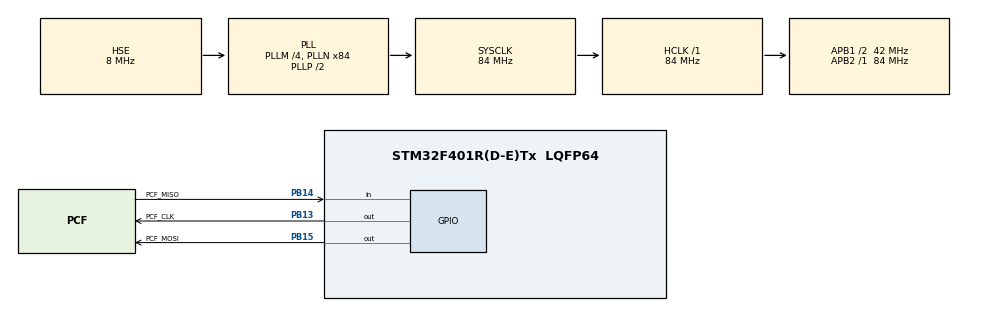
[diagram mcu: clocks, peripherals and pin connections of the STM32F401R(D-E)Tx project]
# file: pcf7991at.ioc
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Mcu.Family=STM32F4
Mcu.Name=STM32F401R(D-E)Tx
Mcu.Package=LQFP64
NVIC.PriorityGroup=NVIC_PRIORITYGROUP_4
PB13.GPIO_Label=PCF_CLK
PB13.GPIO_ModeDefaultOutputPP=GPIO_MODE_OUTPUT_OD
PB13.GPIO_PuPd=GPIO_NOPULL
PB13.GPIO_Speed=GPIO_SPEED_FREQ_HIGH
PB13.Signal=GPIO_Output
PB14.GPIO_Label=PCF_MISO
PB14.Signal=GPIO_Input
PB15.GPIO_Label=PCF_MOSI
PB15.GPIO_ModeDefaultOutputPP=GPIO_MODE_OUTPUT_OD
PB15.GPIO_PuPd=GPIO_NOPULL
PB15.GPIO_Speed=GPIO_SPEED_FREQ_HIGH
PB15.Signal=GPIO_Output
PH0\ -\ OSC_IN.Mode=HSE-External-Oscillator
PH0\ -\ OSC_IN.Signal=RCC_OSC_IN
PH1\ -\ OSC_OUT.Mode=HSE-External-Oscillator
PH1\ -\ OSC_OUT.Signal=RCC_OSC_OUT
ProjectManager.HeapSize=0x200
ProjectManager.StackSize=0x400
ProjectManager.TargetToolchain=STM32CubeIDE
RCC.48MHZClocksFreq_Value=42000000
RCC.AHBFreq_Value=84000000
RCC.APB1CLKDivider=RCC_HCLK_DIV2
RCC.APB1Freq_Value=42000000
RCC.APB1TimFreq_Value=84000000
RCC.APB2Freq_Value=84000000
RCC.APB2TimFreq_Value=84000000
RCC.CortexFreq_Value=84000000
RCC.HCLKFreq_Value=84000000
RCC.HSE_VALUE=8000000
RCC.HSI_VALUE=16000000
RCC.LSE_VALUE=32768
RCC.PLLM=4
RCC.PLLN=84
RCC.PLLSourceVirtual=RCC_PLLSOURCE_HSE
RCC.SYSCLKFreq_VALUE=84000000
RCC.SYSCLKSource=RCC_SYSCLKSOURCE_PLLCLK
RCC.VCOOutputFreq_Value=168000000
board=custom

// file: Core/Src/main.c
/* USER CODE BEGIN Header */
/**
  ******************************************************************************
  * @file           : main.c
  * @brief          : Main program body
  ******************************************************************************
  */
/* USER CODE END Header */
#include "main.h"

void SystemClock_Config(void);
static void MX_GPIO_Init(void);

/* USER CODE BEGIN 0 */

// --- PCF7991AT Pin Macros ---
#define SCK_H()  HAL_GPIO_WritePin(GPIOB, GPIO_PIN_13, GPIO_PIN_SET)
#define SCK_L()  HAL_GPIO_WritePin(GPIOB, GPIO_PIN_13, GPIO_PIN_RESET)
#define MOSI_H() HAL_GPIO_WritePin(GPIOB, GPIO_PIN_15, GPIO_PIN_SET)
#define MOSI_L() HAL_GPIO_WritePin(GPIOB, GPIO_PIN_15, GPIO_PIN_RESET)
#define MISO_R() HAL_GPIO_ReadPin(GPIOB, GPIO_PIN_14)

void PCF_Delay(uint32_t count) {

    for(volatile uint32_t i = 0; i < count; i++) {

        __NOP();

    }

}

void PCF_InitSync(void) {

    SCK_H();
    PCF_Delay(1000);

    MOSI_H();
    PCF_Delay(1000);

    SCK_L();
    PCF_Delay(1000);

}

uint8_t PCF_WriteRead(uint8_t cmd) {

	PCF_InitSync();

    uint8_t response = 0;

    for (int i = 7; i >= 0; i--) {

        if (cmd & (1 << i)) { MOSI_H(); } else { MOSI_L(); }

        PCF_Delay(1000);
        SCK_H();
        PCF_Delay(1000);
        SCK_L();
        PCF_Delay(1000);

    }

    MOSI_L();
    PCF_Delay(1000);

    for (int i = 7; i >= 0; i--) {

        SCK_H();
        PCF_Delay(1000);

        if (MISO_R() == GPIO_PIN_SET) {

            response |= (1 << i);

        }

        SCK_L();
        PCF_Delay(1000);

    }

    return response;

}

void PCF_Write(uint8_t cmd){

	PCF_InitSync();

    for (int i = 7; i >= 0; i--) {

        if (cmd & (1 << i)) { MOSI_H(); } else { MOSI_L(); }

        PCF_Delay(1000);
        SCK_H();
        PCF_Delay(1000);
        SCK_L();
        PCF_Delay(1000);

    }

    MOSI_L();

}

/* USER CODE END 0 */

int main(void)
{

  /* MCU Configuration--------------------------------------------------------*/

  /* Reset of all peripherals, Initializes the Flash interface and the Systick. */
  HAL_Init();

  /* Configure the system clock */
  SystemClock_Config();

  /* Initialize all configured peripherals */
  MX_GPIO_Init();
  /* USER CODE BEGIN 2 */

  HAL_Delay(100);

  //turn off 5V square wave immediately before starting
  PCF_Write(0b01010001);
  HAL_Delay(10);

  //configure page 0
  PCF_Write(0b01000011);
  //configure page 1
  PCF_Write(0b01010011);
  //configure page 2
  PCF_Write(0b01100000);
  //configure page 3
  PCF_Write(0b01111000);

  //turning on 5V square waves
  PCF_Write(0b01010010);
  HAL_Delay(100);

  //storing ACQAMP
  PCF_Write(0b01100100);
  HAL_Delay(10);
  PCF_Write(0b01100000);

  //reading phase
  uint8_t phase = PCF_WriteRead(0b00001000);
  //write the sampling time
  phase &= 0b00111111;
  phase *= 2;
  if(phase > 0b00111111){
    phase = 0b00111111;
  }
  PCF_Write(0b10000000 + phase);
  HAL_Delay(100);

  //starting the read, bits should be available on the MISO line
  PCF_Write(0b11100000);

  /* USER CODE END 2 */

  /* Infinite loop */
  while (1)
  {

  }
}

void SystemClock_Config(void)
{
  RCC_OscInitTypeDef RCC_OscInitStruct = {0};
  RCC_ClkInitTypeDef RCC_ClkInitStruct = {0};

  /** Configure the main internal regulator output voltage
  */
  __HAL_RCC_PWR_CLK_ENABLE();
  __HAL_PWR_VOLTAGESCALING_CONFIG(PWR_REGULATOR_VOLTAGE_SCALE2);

  /** Initializes the RCC Oscillators according to the specified parameters
  * in the RCC_OscInitTypeDef structure.
  */
  RCC_OscInitStruct.OscillatorType = RCC_OSCILLATORTYPE_HSE;
  RCC_OscInitStruct.HSEState = RCC_HSE_ON;
  RCC_OscInitStruct.PLL.PLLState = RCC_PLL_ON;
  RCC_OscInitStruct.PLL.PLLSource = RCC_PLLSOURCE_HSE;
  RCC_OscInitStruct.PLL.PLLM = 4;
  RCC_OscInitStruct.PLL.PLLN = 84;
  RCC_OscInitStruct.PLL.PLLP = RCC_PLLP_DIV2;
  RCC_OscInitStruct.PLL.PLLQ = 4;
  if (HAL_RCC_OscConfig(&RCC_OscInitStruct) != HAL_OK)
  {
    Error_Handler();
  }

  /** Initializes the CPU, AHB and APB buses clocks
  */
  RCC_ClkInitStruct.ClockType = RCC_CLOCKTYPE_HCLK|RCC_CLOCKTYPE_SYSCLK
                              |RCC_CLOCKTYPE_PCLK1|RCC_CLOCKTYPE_PCLK2;
  RCC_ClkInitStruct.SYSCLKSource = RCC_SYSCLKSOURCE_PLLCLK;
  RCC_ClkInitStruct.AHBCLKDivider = RCC_SYSCLK_DIV1;
  RCC_ClkInitStruct.APB1CLKDivider = RCC_HCLK_DIV2;
  RCC_ClkInitStruct.APB2CLKDivider = RCC_HCLK_DIV1;

  if (HAL_RCC_ClockConfig(&RCC_ClkInitStruct, FLASH_LATENCY_2) != HAL_OK)
  {
    Error_Handler();
  }
}

static void MX_GPIO_Init(void)
{
  GPIO_InitTypeDef GPIO_InitStruct = {0};

  /* GPIO Ports Clock Enable */
  __HAL_RCC_GPIOH_CLK_ENABLE();
  __HAL_RCC_GPIOB_CLK_ENABLE();

  /*Configure GPIO pin Output Level */
  HAL_GPIO_WritePin(GPIOB, PCF_CLK_Pin|PCF_MOSI_Pin, GPIO_PIN_RESET);

  /*Configure GPIO pins : PCF_CLK_Pin PCF_MOSI_Pin */
  GPIO_InitStruct.Pin = PCF_CLK_Pin|PCF_MOSI_Pin;
  GPIO_InitStruct.Mode = GPIO_MODE_OUTPUT_OD;
  GPIO_InitStruct.Pull = GPIO_NOPULL;
  GPIO_InitStruct.Speed = GPIO_SPEED_FREQ_HIGH;
  HAL_GPIO_Init(GPIOB, &GPIO_InitStruct);

  /*Configure GPIO pin : PCF_MISO_Pin */
  GPIO_InitStruct.Pin = PCF_MISO_Pin;
  GPIO_InitStruct.Mode = GPIO_MODE_INPUT;
  GPIO_InitStruct.Pull = GPIO_NOPULL;
  HAL_GPIO_Init(PCF_MISO_GPIO_Port, &GPIO_InitStruct);

}

void Error_Handler(void)
{
  __disable_irq();
  while (1)
  {
  }
}
